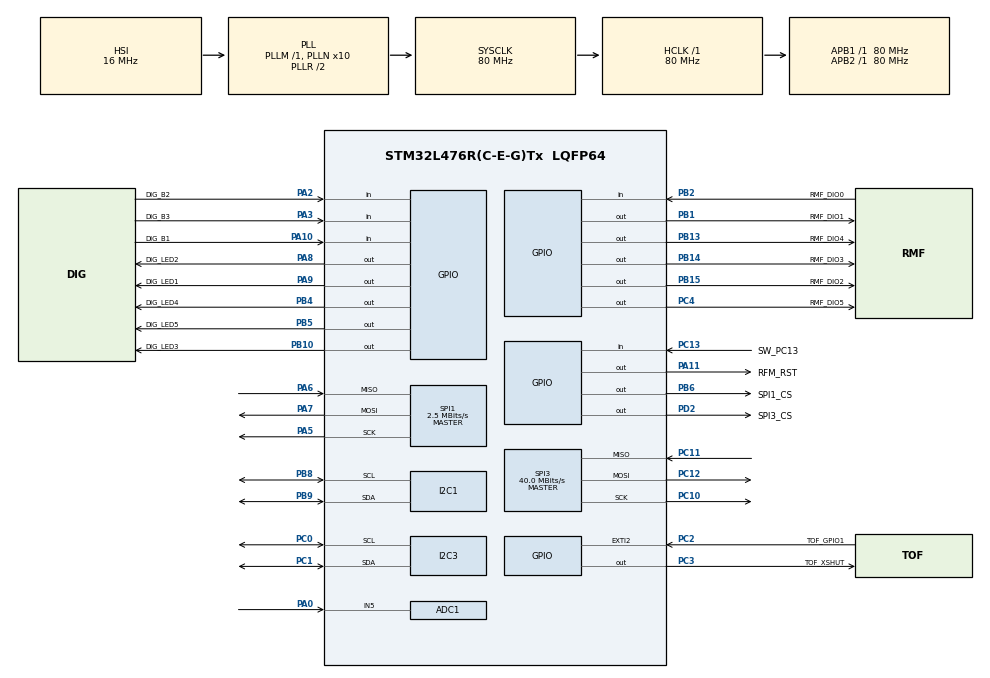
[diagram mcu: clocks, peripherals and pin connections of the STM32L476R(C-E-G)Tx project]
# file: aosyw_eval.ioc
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ADC1.Channel-0\#ChannelRegularConversion=ADC_CHANNEL_5
ADC1.NbrOfConversionFlag=1
ADC1.OffsetNumber-0\#ChannelRegularConversion=ADC_OFFSET_NONE
ADC1.Rank-0\#ChannelRegularConversion=1
ADC1.SamplingTime-0\#ChannelRegularConversion=ADC_SAMPLETIME_2CYCLES_5
ADC1.master=1
FREERTOS.Tasks01=defaultTask,0,128,StartDefaultTask,Default,NULL,Dynamic,NULL,NULL
I2C1.Timing=0x10D19CE4
I2C3.Timing=0x10D19CE4
Mcu.Family=STM32L4
Mcu.Name=STM32L476R(C-E-G)Tx
Mcu.Package=LQFP64
NVIC.PriorityGroup=NVIC_PRIORITYGROUP_4
NVIC.TIM6_DAC_IRQn=true\:15\:0\:false\:false\:true\:false\:false\:true\:true
NVIC.TimeBase=TIM6_DAC_IRQn
NVIC.TimeBaseIP=TIM6
PA0.Signal=ADCx_IN5
PA10.GPIO_Label=DIG_B1
PA10.Signal=GPIO_Input
PA11.GPIO_Label=RFM_RST
PA11.Signal=GPIO_Output
PA13\ (JTMS-SWDIO).GPIO_Label=TMS
PA13\ (JTMS-SWDIO).Mode=Serial_Wire
PA13\ (JTMS-SWDIO).Signal=SYS_JTMS-SWDIO
PA14\ (JTCK-SWCLK).GPIO_Label=TCK
PA14\ (JTCK-SWCLK).Mode=Serial_Wire
PA14\ (JTCK-SWCLK).Signal=SYS_JTCK-SWCLK
PA2.GPIO_Label=DIG_B2
PA2.Signal=GPIO_Input
PA3.GPIO_Label=DIG_B3
PA3.Signal=GPIO_Input
PA5.Mode=Full_Duplex_Master
PA5.Signal=SPI1_SCK
PA6.Mode=Full_Duplex_Master
PA6.Signal=SPI1_MISO
PA7.Mode=Full_Duplex_Master
PA7.Signal=SPI1_MOSI
PA8.GPIO_Label=DIG_LED2
PA8.Signal=GPIO_Output
PA9.GPIO_Label=DIG_LED1
PA9.Signal=GPIO_Output
PB1.GPIO_Label=RMF_DIO1
PB1.Signal=GPIO_Output
PB10.GPIO_Label=DIG_LED3
PB10.Signal=GPIO_Output
PB13.GPIO_Label=RMF_DIO4
PB13.Signal=GPIO_Output
PB14.GPIO_Label=RMF_DIO3
PB14.Signal=GPIO_Output
PB15.GPIO_Label=RMF_DIO2
PB15.Signal=GPIO_Output
PB2.GPIO_Label=RMF_DIO0
PB2.Signal=GPIO_Input
PB3\ (JTDO-TRACESWO).GPIO_Label=SWO
PB3\ (JTDO-TRACESWO).Signal=SYS_JTDO-SWO
PB4\ (NJTRST).GPIO_Label=DIG_LED4
PB4\ (NJTRST).Signal=GPIO_Output
PB5.GPIO_Label=DIG_LED5
PB5.Signal=GPIO_Output
PB6.GPIO_Label=SPI1_CS
PB6.Signal=GPIO_Output
PB8.Mode=I2C
PB8.Signal=I2C1_SCL
PB9.Mode=I2C
PB9.Signal=I2C1_SDA
PC0.Mode=I2C
PC0.Signal=I2C3_SCL
PC1.Mode=I2C
PC1.Signal=I2C3_SDA
PC10.Mode=Full_Duplex_Master
PC10.Signal=SPI3_SCK
PC11.Mode=Full_Duplex_Master
PC11.Signal=SPI3_MISO
PC12.Mode=Full_Duplex_Master
PC12.Signal=SPI3_MOSI
PC13.GPIO_Label=SW_PC13
PC13.Signal=GPIO_Input
PC14-OSC32_IN\ (PC14).Mode=LSE-External-Oscillator
PC14-OSC32_IN\ (PC14).Signal=RCC_OSC32_IN
PC15-OSC32_OUT\ (PC15).Mode=LSE-External-Oscillator
PC15-OSC32_OUT\ (PC15).Signal=RCC_OSC32_OUT
PC2.GPIO_Label=TOF_GPIO1
PC2.Signal=GPXTI2
PC3.GPIO_Label=TOF_XSHUT
PC3.GPIO_PuPd=GPIO_PULLUP
PC3.PinState=GPIO_PIN_RESET
PC3.Signal=GPIO_Output
PC4.GPIO_Label=RMF_DIO5
PC4.Signal=GPIO_Output
PD2.GPIO_Label=SPI3_CS
PD2.Signal=GPIO_Output
PH0-OSC_IN\ (PH0).Signal=RCC_OSC_IN
PH1-OSC_OUT\ (PH1).Signal=RCC_OSC_OUT
ProjectManager.HeapSize=0x200
ProjectManager.StackSize=0x400
ProjectManager.TargetToolchain=CMake
RCC.ADCFreq_Value=64000000
RCC.AHBFreq_Value=80000000
RCC.APB1Freq_Value=80000000
RCC.APB1TimFreq_Value=80000000
RCC.APB2Freq_Value=80000000
RCC.APB2TimFreq_Value=80000000
RCC.CortexFreq_Value=80000000
RCC.HCLKFreq_Value=80000000
RCC.HSE_VALUE=8000000
RCC.HSI_VALUE=16000000
RCC.MSI_VALUE=4000000
RCC.PLLN=10
RCC.PLLSourceVirtual=RCC_PLLSOURCE_HSI
RCC.PREFETCH_ENABLE=1
RCC.SYSCLKFreq_VALUE=80000000
RCC.SYSCLKSource=RCC_SYSCLKSOURCE_PLLCLK
RCC.USBFreq_Value=64000000
RCC.VCOOutputFreq_Value=160000000
SH.ADCx_IN5.0=ADC1_IN5,IN5-Single-Ended
SPI1.BaudRatePrescaler=SPI_BAUDRATEPRESCALER_32
SPI1.CalculateBaudRate=2.5 MBits/s
SPI1.DataSize=SPI_DATASIZE_8BIT
SPI1.Direction=SPI_DIRECTION_2LINES
SPI1.Mode=SPI_MODE_MASTER
SPI1.VirtualNSS=VM_NSSHARD
SPI1.VirtualType=VM_MASTER
SPI3.CalculateBaudRate=40.0 MBits/s
SPI3.Direction=SPI_DIRECTION_2LINES
SPI3.Mode=SPI_MODE_MASTER
SPI3.VirtualNSS=VM_NSSHARD
SPI3.VirtualType=VM_MASTER
VP_FREERTOS_VS_CMSIS_V1.Mode=CMSIS_V1
VP_SYS_VS_tim6.Mode=TIM6
board=NUCLEO-L476RG

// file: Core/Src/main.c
/* USER CODE BEGIN Header */
/**
 ******************************************************************************
 * @file           : main.c
 * @brief          : Main program body
 ******************************************************************************
 * @attention
 *
 * Copyright (c) 2024 STMicroelectronics.
 * All rights reserved.
 *
 * This software is licensed under terms that can be found in the LICENSE file
 * in the root directory of this software component.
 * If no LICENSE file comes with this software, it is provided AS-IS.
 *
 ******************************************************************************
 */
/* USER CODE END Header */
#include "main.h"
#include "cmsis_os.h"

/* USER CODE BEGIN Includes */
#include "../../app/include/app_core.h"
#include "stm_headers.h"
#include OLED_DRIVER

/* USER CODE END Includes */

ADC_HandleTypeDef hadc1;

I2C_HandleTypeDef hi2c1;
I2C_HandleTypeDef hi2c3;

SPI_HandleTypeDef hspi1;
SPI_HandleTypeDef hspi3;

osThreadId defaultTaskHandle;

void SystemClock_Config(void);
static void MX_GPIO_Init(void);
static void MX_I2C1_Init(void);
static void MX_I2C3_Init(void);
static void MX_SPI1_Init(void);
static void MX_SPI3_Init(void);
static void MX_ADC1_Init(void);
void StartDefaultTask(void const * argument);

int main(void)
{

  /* MCU Configuration--------------------------------------------------------*/

  /* Reset of all peripherals, Initializes the Flash interface and the Systick. */
  HAL_Init();

  /* Configure the system clock */
  SystemClock_Config();

  /* Initialize all configured peripherals */
  MX_GPIO_Init();
  MX_I2C1_Init();
  MX_I2C3_Init();
  MX_SPI1_Init();
  MX_SPI3_Init();
  MX_ADC1_Init();
  /* USER CODE BEGIN 2 */
    ssd1306_Init();
    start();
  /* USER CODE END 2 */

  /* Create the thread(s) */
  /* definition and creation of defaultTask */
  osThreadDef(defaultTask, StartDefaultTask, osPriorityNormal, 0, 128);
  defaultTaskHandle = osThreadCreate(osThread(defaultTask), NULL);

  /* Start scheduler */
  osKernelStart();

  /* We should never get here as control is now taken by the scheduler */

  /* Infinite loop */
    while (1) {

    }
}

void SystemClock_Config(void)
{
  RCC_OscInitTypeDef RCC_OscInitStruct = {0};
  RCC_ClkInitTypeDef RCC_ClkInitStruct = {0};

  /** Configure the main internal regulator output voltage
  */
  if (HAL_PWREx_ControlVoltageScaling(PWR_REGULATOR_VOLTAGE_SCALE1) != HAL_OK)
  {
    Error_Handler();
  }

  /** Initializes the RCC Oscillators according to the specified parameters
  * in the RCC_OscInitTypeDef structure.
  */
  RCC_OscInitStruct.OscillatorType = RCC_OSCILLATORTYPE_HSI;
  RCC_OscInitStruct.HSIState = RCC_HSI_ON;
  RCC_OscInitStruct.HSICalibrationValue = RCC_HSICALIBRATION_DEFAULT;
  RCC_OscInitStruct.PLL.PLLState = RCC_PLL_ON;
  RCC_OscInitStruct.PLL.PLLSource = RCC_PLLSOURCE_HSI;
  RCC_OscInitStruct.PLL.PLLM = 1;
  RCC_OscInitStruct.PLL.PLLN = 10;
  RCC_OscInitStruct.PLL.PLLP = RCC_PLLP_DIV7;
  RCC_OscInitStruct.PLL.PLLQ = RCC_PLLQ_DIV2;
  RCC_OscInitStruct.PLL.PLLR = RCC_PLLR_DIV2;
  if (HAL_RCC_OscConfig(&RCC_OscInitStruct) != HAL_OK)
  {
    Error_Handler();
  }

  /** Initializes the CPU, AHB and APB buses clocks
  */
  RCC_ClkInitStruct.ClockType = RCC_CLOCKTYPE_HCLK|RCC_CLOCKTYPE_SYSCLK
                              |RCC_CLOCKTYPE_PCLK1|RCC_CLOCKTYPE_PCLK2;
  RCC_ClkInitStruct.SYSCLKSource = RCC_SYSCLKSOURCE_PLLCLK;
  RCC_ClkInitStruct.AHBCLKDivider = RCC_SYSCLK_DIV1;
  RCC_ClkInitStruct.APB1CLKDivider = RCC_HCLK_DIV1;
  RCC_ClkInitStruct.APB2CLKDivider = RCC_HCLK_DIV1;

  if (HAL_RCC_ClockConfig(&RCC_ClkInitStruct, FLASH_LATENCY_4) != HAL_OK)
  {
    Error_Handler();
  }
}

static void MX_ADC1_Init(void)
{

  ADC_MultiModeTypeDef multimode = {0};
  ADC_ChannelConfTypeDef sConfig = {0};

  /** Common config
  */
  hadc1.Instance = ADC1;
  hadc1.Init.ClockPrescaler = ADC_CLOCK_ASYNC_DIV1;
  hadc1.Init.Resolution = ADC_RESOLUTION_12B;
  hadc1.Init.DataAlign = ADC_DATAALIGN_RIGHT;
  hadc1.Init.ScanConvMode = ADC_SCAN_DISABLE;
  hadc1.Init.EOCSelection = ADC_EOC_SINGLE_CONV;
  hadc1.Init.LowPowerAutoWait = DISABLE;
  hadc1.Init.ContinuousConvMode = DISABLE;
  hadc1.Init.NbrOfConversion = 1;
  hadc1.Init.DiscontinuousConvMode = DISABLE;
  hadc1.Init.ExternalTrigConv = ADC_SOFTWARE_START;
  hadc1.Init.ExternalTrigConvEdge = ADC_EXTERNALTRIGCONVEDGE_NONE;
  hadc1.Init.DMAContinuousRequests = DISABLE;
  hadc1.Init.Overrun = ADC_OVR_DATA_PRESERVED;
  hadc1.Init.OversamplingMode = DISABLE;
  if (HAL_ADC_Init(&hadc1) != HAL_OK)
  {
    Error_Handler();
  }

  /** Configure the ADC multi-mode
  */
  multimode.Mode = ADC_MODE_INDEPENDENT;
  if (HAL_ADCEx_MultiModeConfigChannel(&hadc1, &multimode) != HAL_OK)
  {
    Error_Handler();
  }

  /** Configure Regular Channel
  */
  sConfig.Channel = ADC_CHANNEL_5;
  sConfig.Rank = ADC_REGULAR_RANK_1;
  sConfig.SamplingTime = ADC_SAMPLETIME_2CYCLES_5;
  sConfig.SingleDiff = ADC_SINGLE_ENDED;
  sConfig.OffsetNumber = ADC_OFFSET_NONE;
  sConfig.Offset = 0;
  if (HAL_ADC_ConfigChannel(&hadc1, &sConfig) != HAL_OK)
  {
    Error_Handler();
  }

}

static void MX_I2C1_Init(void)
{

  hi2c1.Instance = I2C1;
  hi2c1.Init.Timing = 0x10D19CE4;
  hi2c1.Init.OwnAddress1 = 0;
  hi2c1.Init.AddressingMode = I2C_ADDRESSINGMODE_7BIT;
  hi2c1.Init.DualAddressMode = I2C_DUALADDRESS_DISABLE;
  hi2c1.Init.OwnAddress2 = 0;
  hi2c1.Init.OwnAddress2Masks = I2C_OA2_NOMASK;
  hi2c1.Init.GeneralCallMode = I2C_GENERALCALL_DISABLE;
  hi2c1.Init.NoStretchMode = I2C_NOSTRETCH_DISABLE;
  if (HAL_I2C_Init(&hi2c1) != HAL_OK)
  {
    Error_Handler();
  }

  /** Configure Analogue filter
  */
  if (HAL_I2CEx_ConfigAnalogFilter(&hi2c1, I2C_ANALOGFILTER_ENABLE) != HAL_OK)
  {
    Error_Handler();
  }

  /** Configure Digital filter
  */
  if (HAL_I2CEx_ConfigDigitalFilter(&hi2c1, 0) != HAL_OK)
  {
    Error_Handler();
  }

}

static void MX_I2C3_Init(void)
{

  hi2c3.Instance = I2C3;
  hi2c3.Init.Timing = 0x10D19CE4;
  hi2c3.Init.OwnAddress1 = 0;
  hi2c3.Init.AddressingMode = I2C_ADDRESSINGMODE_7BIT;
  hi2c3.Init.DualAddressMode = I2C_DUALADDRESS_DISABLE;
  hi2c3.Init.OwnAddress2 = 0;
  hi2c3.Init.OwnAddress2Masks = I2C_OA2_NOMASK;
  hi2c3.Init.GeneralCallMode = I2C_GENERALCALL_DISABLE;
  hi2c3.Init.NoStretchMode = I2C_NOSTRETCH_DISABLE;
  if (HAL_I2C_Init(&hi2c3) != HAL_OK)
  {
    Error_Handler();
  }

  /** Configure Analogue filter
  */
  if (HAL_I2CEx_ConfigAnalogFilter(&hi2c3, I2C_ANALOGFILTER_ENABLE) != HAL_OK)
  {
    Error_Handler();
  }

  /** Configure Digital filter
  */
  if (HAL_I2CEx_ConfigDigitalFilter(&hi2c3, 0) != HAL_OK)
  {
    Error_Handler();
  }

}

static void MX_SPI1_Init(void)
{

  /* SPI1 parameter configuration*/
  hspi1.Instance = SPI1;
  hspi1.Init.Mode = SPI_MODE_MASTER;
  hspi1.Init.Direction = SPI_DIRECTION_2LINES;
  hspi1.Init.DataSize = SPI_DATASIZE_8BIT;
  hspi1.Init.CLKPolarity = SPI_POLARITY_LOW;
  hspi1.Init.CLKPhase = SPI_PHASE_1EDGE;
  hspi1.Init.NSS = SPI_NSS_SOFT;
  hspi1.Init.BaudRatePrescaler = SPI_BAUDRATEPRESCALER_32;
  hspi1.Init.FirstBit = SPI_FIRSTBIT_MSB;
  hspi1.Init.TIMode = SPI_TIMODE_DISABLE;
  hspi1.Init.CRCCalculation = SPI_CRCCALCULATION_DISABLE;
  hspi1.Init.CRCPolynomial = 7;
  hspi1.Init.CRCLength = SPI_CRC_LENGTH_DATASIZE;
  hspi1.Init.NSSPMode = SPI_NSS_PULSE_ENABLE;
  if (HAL_SPI_Init(&hspi1) != HAL_OK)
  {
    Error_Handler();
  }

}

static void MX_SPI3_Init(void)
{

  /* SPI3 parameter configuration*/
  hspi3.Instance = SPI3;
  hspi3.Init.Mode = SPI_MODE_MASTER;
  hspi3.Init.Direction = SPI_DIRECTION_2LINES;
  hspi3.Init.DataSize = SPI_DATASIZE_4BIT;
  hspi3.Init.CLKPolarity = SPI_POLARITY_LOW;
  hspi3.Init.CLKPhase = SPI_PHASE_1EDGE;
  hspi3.Init.NSS = SPI_NSS_SOFT;
  hspi3.Init.BaudRatePrescaler = SPI_BAUDRATEPRESCALER_2;
  hspi3.Init.FirstBit = SPI_FIRSTBIT_MSB;
  hspi3.Init.TIMode = SPI_TIMODE_DISABLE;
  hspi3.Init.CRCCalculation = SPI_CRCCALCULATION_DISABLE;
  hspi3.Init.CRCPolynomial = 7;
  hspi3.Init.CRCLength = SPI_CRC_LENGTH_DATASIZE;
  hspi3.Init.NSSPMode = SPI_NSS_PULSE_ENABLE;
  if (HAL_SPI_Init(&hspi3) != HAL_OK)
  {
    Error_Handler();
  }

}

static void MX_GPIO_Init(void)
{
  GPIO_InitTypeDef GPIO_InitStruct = {0};

  /* GPIO Ports Clock Enable */
  __HAL_RCC_GPIOC_CLK_ENABLE();
  __HAL_RCC_GPIOH_CLK_ENABLE();
  __HAL_RCC_GPIOA_CLK_ENABLE();
  __HAL_RCC_GPIOB_CLK_ENABLE();
  __HAL_RCC_GPIOD_CLK_ENABLE();

  /*Configure GPIO pin Output Level */
  HAL_GPIO_WritePin(GPIOC, TOF_XSHUT_Pin|RMF_DIO5_Pin, GPIO_PIN_RESET);

  /*Configure GPIO pin Output Level */
  HAL_GPIO_WritePin(GPIOB, RMF_DIO1_Pin|DIG_LED3_Pin|RMF_DIO4_Pin|RMF_DIO3_Pin
                          |RMF_DIO2_Pin|DIG_LED4_Pin|DIG_LED5_Pin|SPI1_CS_Pin, GPIO_PIN_RESET);

  /*Configure GPIO pin Output Level */
  HAL_GPIO_WritePin(GPIOA, DIG_LED2_Pin|DIG_LED1_Pin|RFM_RST_Pin, GPIO_PIN_RESET);

  /*Configure GPIO pin Output Level */
  HAL_GPIO_WritePin(SPI3_CS_GPIO_Port, SPI3_CS_Pin, GPIO_PIN_RESET);

  /*Configure GPIO pin : SW_PC13_Pin */
  GPIO_InitStruct.Pin = SW_PC13_Pin;
  GPIO_InitStruct.Mode = GPIO_MODE_INPUT;
  GPIO_InitStruct.Pull = GPIO_NOPULL;
  HAL_GPIO_Init(SW_PC13_GPIO_Port, &GPIO_InitStruct);

  /*Configure GPIO pin : TOF_GPIO1_Pin */
  GPIO_InitStruct.Pin = TOF_GPIO1_Pin;
  GPIO_InitStruct.Mode = GPIO_MODE_IT_RISING;
  GPIO_InitStruct.Pull = GPIO_NOPULL;
  HAL_GPIO_Init(TOF_GPIO1_GPIO_Port, &GPIO_InitStruct);

  /*Configure GPIO pin : TOF_XSHUT_Pin */
  GPIO_InitStruct.Pin = TOF_XSHUT_Pin;
  GPIO_InitStruct.Mode = GPIO_MODE_OUTPUT_PP;
  GPIO_InitStruct.Pull = GPIO_PULLUP;
  GPIO_InitStruct.Speed = GPIO_SPEED_FREQ_LOW;
  HAL_GPIO_Init(TOF_XSHUT_GPIO_Port, &GPIO_InitStruct);

  /*Configure GPIO pins : DIG_B2_Pin DIG_B3_Pin DIG_B1_Pin */
  GPIO_InitStruct.Pin = DIG_B2_Pin|DIG_B3_Pin|DIG_B1_Pin;
  GPIO_InitStruct.Mode = GPIO_MODE_INPUT;
  GPIO_InitStruct.Pull = GPIO_NOPULL;
  HAL_GPIO_Init(GPIOA, &GPIO_InitStruct);

  /*Configure GPIO pin : RMF_DIO5_Pin */
  GPIO_InitStruct.Pin = RMF_DIO5_Pin;
  GPIO_InitStruct.Mode = GPIO_MODE_OUTPUT_PP;
  GPIO_InitStruct.Pull = GPIO_NOPULL;
  GPIO_InitStruct.Speed = GPIO_SPEED_FREQ_LOW;
  HAL_GPIO_Init(RMF_DIO5_GPIO_Port, &GPIO_InitStruct);

  /*Configure GPIO pins : RMF_DIO1_Pin DIG_LED3_Pin RMF_DIO4_Pin RMF_DIO3_Pin
                           RMF_DIO2_Pin DIG_LED4_Pin DIG_LED5_Pin SPI1_CS_Pin */
  GPIO_InitStruct.Pin = RMF_DIO1_Pin|DIG_LED3_Pin|RMF_DIO4_Pin|RMF_DIO3_Pin
                          |RMF_DIO2_Pin|DIG_LED4_Pin|DIG_LED5_Pin|SPI1_CS_Pin;
  GPIO_InitStruct.Mode = GPIO_MODE_OUTPUT_PP;
  GPIO_InitStruct.Pull = GPIO_NOPULL;
  GPIO_InitStruct.Speed = GPIO_SPEED_FREQ_LOW;
  HAL_GPIO_Init(GPIOB, &GPIO_InitStruct);

  /*Configure GPIO pin : RMF_DIO0_Pin */
  GPIO_InitStruct.Pin = RMF_DIO0_Pin;
  GPIO_InitStruct.Mode = GPIO_MODE_INPUT;
  GPIO_InitStruct.Pull = GPIO_NOPULL;
  HAL_GPIO_Init(RMF_DIO0_GPIO_Port, &GPIO_InitStruct);

  /*Configure GPIO pins : DIG_LED2_Pin DIG_LED1_Pin RFM_RST_Pin */
  GPIO_InitStruct.Pin = DIG_LED2_Pin|DIG_LED1_Pin|RFM_RST_Pin;
  GPIO_InitStruct.Mode = GPIO_MODE_OUTPUT_PP;
  GPIO_InitStruct.Pull = GPIO_NOPULL;
  GPIO_InitStruct.Speed = GPIO_SPEED_FREQ_LOW;
  HAL_GPIO_Init(GPIOA, &GPIO_InitStruct);

  /*Configure GPIO pin : SPI3_CS_Pin */
  GPIO_InitStruct.Pin = SPI3_CS_Pin;
  GPIO_InitStruct.Mode = GPIO_MODE_OUTPUT_PP;
  GPIO_InitStruct.Pull = GPIO_NOPULL;
  GPIO_InitStruct.Speed = GPIO_SPEED_FREQ_LOW;
  HAL_GPIO_Init(SPI3_CS_GPIO_Port, &GPIO_InitStruct);

}

void StartDefaultTask(void const * argument)
{
    for (;;) {
        osDelay(1);
    }
}

void HAL_TIM_PeriodElapsedCallback(TIM_HandleTypeDef *htim)
{
  if (htim->Instance == TIM6) {
    HAL_IncTick();
  }
}

void Error_Handler(void)
{
  /* USER CODE BEGIN Error_Handler_Debug */
    /* User can add his own implementation to report the HAL error return state
     */
    __disable_irq();
    while (1) {
    }
  /* USER CODE END Error_Handler_Debug */
}

#ifdef  USE_FULL_ASSERT
/**
  * @brief  Reports the name of the source file and the source line number
  *         where the assert_param error has occurred.
  * @param  file: pointer to the source file name
  * @param  line: assert_param error line source number
  * @retval None
  */
void assert_failed(uint8_t *file, uint32_t line)
{
  /* USER CODE BEGIN 6 */
    /* User can add his own implementation to report the file name and line
       number, ex: printf("Wrong parameters value: file %s on line %d\r\n",
       file, line) */
  /* USER CODE END 6 */
}
#endif /* USE_FULL_ASSERT */
